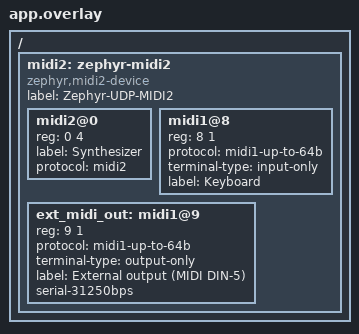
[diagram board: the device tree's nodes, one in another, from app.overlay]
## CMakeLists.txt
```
# Copyright (c) 2025 Titouan Christophe
# SPDX-License-Identifier: Apache-2.0

cmake_minimum_required(VERSION 3.28.0)

find_package(Zephyr REQUIRED HINTS $ENV{ZEPHYR_BASE})
project(netmidi2)

FILE(GLOB app_sources src/*.c)
target_sources(app PRIVATE ${app_sources})

include(${ZEPHYR_BASE}/samples/net/common/common.cmake)
```

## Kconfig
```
# Copyright (c) 2025 Titouan Christophe
# SPDX-License-Identifier: Apache-2.0

menu "Networking MIDI2 sample application"

config NET_SAMPLE_MIDI2_ACTIVITY_LED
	bool "Light up an LED while sending on the serial MIDI1 port"
	depends on $(dt_nodelabel_enabled,midi_green_led)
	select GPIO
	default y

choice NET_SAMPLE_MIDI2_AUTH_TYPE
	prompt "UMP Endpoint authentication method"
	default NET_SAMPLE_MIDI2_AUTH_NONE

config NET_SAMPLE_MIDI2_AUTH_NONE
	bool "No authentication"

config NET_SAMPLE_MIDI2_AUTH_SHARED_SECRET
	bool "Authentication with shared secret"
	select NETMIDI2_HOST_AUTH

config NET_SAMPLE_MIDI2_AUTH_USER_PASSWORD
	bool "Authentication with username+password"
	select NETMIDI2_HOST_AUTH

endchoice

config NET_SAMPLE_MIDI2_SHARED_SECRET
	string "Shared secret"
	depends on NET_SAMPLE_MIDI2_AUTH_SHARED_SECRET

config NET_SAMPLE_MIDI2_USERNAME
	string "Username"
	depends on NET_SAMPLE_MIDI2_AUTH_USER_PASSWORD

config NET_SAMPLE_MIDI2_PASSWORD
	string "Password"
	depends on NET_SAMPLE_MIDI2_AUTH_USER_PASSWORD

endmenu

source "Kconfig.zephyr"
```

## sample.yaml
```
common:
  harness: net
  depends_on: netif
  tags:
    - net
    - midi2
    - fdtable
sample:
  name: Network MIDI2.0 sample application
  description: Demonstrates usage of the Network MIDI2.0 (udp) host endpoint
tests:
  sample.net.midi2.host: {}
  sample.net.midi2.host_auth_shared:
    extra_configs:
      - CONFIG_NET_SAMPLE_MIDI2_AUTH_SHARED_SECRET=y
      - CONFIG_NET_SAMPLE_MIDI2_SHARED_SECRET="some-secret"
  sample.net.midi2.host_auth_user:
    extra_configs:
      - CONFIG_NET_SAMPLE_MIDI2_AUTH_USER_PASSWORD=y
      - CONFIG_NET_SAMPLE_MIDI2_USERNAME="user"
      - CONFIG_NET_SAMPLE_MIDI2_PASSWORD="passwd"
```

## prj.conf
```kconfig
CONFIG_NETWORKING=y
CONFIG_ZVFS_POLL_MAX=4
CONFIG_NET_IF_MCAST_IPV6_ADDR_COUNT=5
CONFIG_NET_CONFIG_SETTINGS=y
CONFIG_NET_CONFIG_NEED_IPV6=y
CONFIG_NET_CONFIG_MY_IPV6_ADDR="2001:db8::1"
CONFIG_NET_CONFIG_NEED_IPV4=y
CONFIG_NET_CONFIG_MY_IPV4_ADDR="192.0.2.1"

CONFIG_NET_HOSTNAME_ENABLE=y
CONFIG_MDNS_RESPONDER=y
CONFIG_DNS_SD=y

CONFIG_NETMIDI2_HOST=y
CONFIG_MIDI2_UMP_STREAM_RESPONDER=y

CONFIG_LOG=y
CONFIG_NET_LOG=y
CONFIG_TEST_RANDOM_GENERATOR=y
```

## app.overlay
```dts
/*
 * Copyright (c) 2025 Titouan Christophe
 * SPDX-License-Identifier: Apache-2.0
 */

/ {
	midi2: zephyr-midi2 {
		compatible = "zephyr,midi2-device";
		#address-cells = <1>;
		#size-cells = <1>;
		label = "Zephyr-UDP-MIDI2";
		status = "okay";

		midi2@0 {
			reg = <0 4>;
			label = "Synthesizer";
			protocol = "midi2";
		};

		midi1@8 {
			reg = <8 1>;
			protocol = "midi1-up-to-64b";
			terminal-type = "input-only";
			label = "Keyboard";
		};

		ext_midi_out: midi1@9 {
			reg = <9 1>;
			protocol = "midi1-up-to-64b";
			terminal-type = "output-only";
			label = "External output (MIDI DIN-5)";
			serial-31250bps;
		};
	};
};
```

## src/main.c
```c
/*
 * Copyright (c) 2025 Titouan Christophe
 * SPDX-License-Identifier: Apache-2.0
 */

#include <zephyr/kernel.h>
#include <errno.h>
#include <stdio.h>

#include <zephyr/audio/midi.h>
#include <zephyr/net/dns_sd.h>
#include <zephyr/net/midi2.h>

#include <ump_stream_responder.h>

#include <zephyr/logging/log.h>
LOG_MODULE_REGISTER(net_midi2_sample, LOG_LEVEL_DBG);

#define ACT_LED_NODE DT_NODELABEL(midi_green_led)
#define SERIAL_NODE  DT_NODELABEL(midi_serial)

#if !defined(CONFIG_NET_SAMPLE_MIDI2_ACTIVITY_LED)
#define CONFIGURE_LED()
#define SET_LED(_state)
#else /* CONFIG_NET_SAMPLE_MIDI2_ACTIVITY_LED */
#include <zephyr/drivers/gpio.h>

static const struct gpio_dt_spec act_led = GPIO_DT_SPEC_GET(ACT_LED_NODE, gpios);

#define CONFIGURE_LED() gpio_pin_configure_dt(&act_led, GPIO_OUTPUT_INACTIVE)
#define SET_LED(_state) gpio_pin_set_dt(&act_led, (_state))
#endif  /* CONFIG_NET_SAMPLE_MIDI2_ACTIVITY_LED */


#if !DT_NODE_EXISTS(SERIAL_NODE)
#define send_external_midi1(...)
#else /* DT_NODE_EXISTS(SERIAL_NODE) */
#include <zephyr/drivers/uart.h>

static const struct device *const uart_dev = DEVICE_DT_GET(SERIAL_NODE);

static inline void send_external_midi1(const struct midi_ump ump)
{
	/* Only send MIDI events aimed at the external output */
	if (UMP_GROUP(ump) != DT_REG_ADDR(DT_NODELABEL(ext_midi_out))) {
		return;
	}

	switch (UMP_MIDI_COMMAND(ump)) {
	case UMP_MIDI_PROGRAM_CHANGE:
		SET_LED(1);
		uart_poll_out(uart_dev, UMP_MIDI_STATUS(ump));
		uart_poll_out(uart_dev, UMP_MIDI1_P1(ump));
		SET_LED(0);
		break;

	case UMP_MIDI_NOTE_OFF:
	case UMP_MIDI_NOTE_ON:
	case UMP_MIDI_AFTERTOUCH:
	case UMP_MIDI_CONTROL_CHANGE:
	case UMP_MIDI_PITCH_BEND:
		SET_LED(1);
		uart_poll_out(uart_dev, UMP_MIDI_STATUS(ump));
		uart_poll_out(uart_dev, UMP_MIDI1_P1(ump));
		uart_poll_out(uart_dev, UMP_MIDI1_P2(ump));
		SET_LED(0);
		break;
	}
}
#endif /* DT_NODE_EXISTS(SERIAL_NODE) */

#define MIDI2_NODE DT_NODELABEL(midi2)

static const struct ump_endpoint_dt_spec ump_ep_dt =
	UMP_ENDPOINT_DT_SPEC_GET(MIDI2_NODE);

static inline void handle_ump_stream(struct netmidi2_session *session,
				     const struct midi_ump ump)
{
	const struct ump_stream_responder_cfg responder_cfg =
		UMP_STREAM_RESPONDER(session, netmidi2_send, &ump_ep_dt);
	ump_stream_respond(&responder_cfg, ump);
}

static void netmidi2_callback(struct netmidi2_session *session,
			      const struct midi_ump ump)
{
	switch (UMP_MT(ump)) {
	case UMP_MT_MIDI1_CHANNEL_VOICE:
		send_external_midi1(ump);
		break;
	case UMP_MT_UMP_STREAM:
		handle_ump_stream(session, ump);
		break;
	}
}

#if defined(CONFIG_NET_SAMPLE_MIDI2_AUTH_NONE)
/* Simple Network MIDI 2.0 endpoint without authentication */
NETMIDI2_EP_DEFINE(midi_server, DT_PROP_OR(MIDI2_NODE, label, NULL), NULL, 0);

#elif defined(CONFIG_NET_SAMPLE_MIDI2_AUTH_SHARED_SECRET)
/* Network MIDI 2.0 endpoint with shared secret authentication */
BUILD_ASSERT(
	sizeof(CONFIG_NET_SAMPLE_MIDI2_SHARED_SECRET) > 1,
	"CONFIG_NET_SAMPLE_MIDI2_SHARED_SECRET must be not empty"
);

NETMIDI2_EP_DEFINE_WITH_AUTH(midi_server, DT_PROP_OR(MIDI2_NODE, label, NULL), NULL, 0,
	CONFIG_NET_SAMPLE_MIDI2_SHARED_SECRET);

#elif defined(CONFIG_NET_SAMPLE_MIDI2_AUTH_USER_PASSWORD)
/* Network MIDI 2.0 endpoint with a single user/password*/
BUILD_ASSERT(
	sizeof(CONFIG_NET_SAMPLE_MIDI2_USERNAME) > 1,
	"CONFIG_NET_SAMPLE_MIDI2_USERNAME must be not empty"
);
BUILD_ASSERT(
	sizeof(CONFIG_NET_SAMPLE_MIDI2_PASSWORD) > 1,
	"CONFIG_NET_SAMPLE_MIDI2_PASSWORD must be not empty"
);

NETMIDI2_EP_DEFINE_WITH_USERS(midi_server, DT_PROP_OR(MIDI2_NODE, label, NULL), NULL, 0,
	{.name = CONFIG_NET_SAMPLE_MIDI2_USERNAME,
	 .password = CONFIG_NET_SAMPLE_MIDI2_PASSWORD});

#endif

DNS_SD_REGISTER_SERVICE(midi_dns, CONFIG_NET_HOSTNAME "-" CONFIG_BOARD,
			"_midi2", "_udp", "local", DNS_SD_EMPTY_TXT,
			&midi_server.addr4.sin_port);

int main(void)
{
	CONFIGURE_LED();

	midi_server.rx_packet_cb = netmidi2_callback;
	netmidi2_host_ep_start(&midi_server);

	return 0;
}
```
